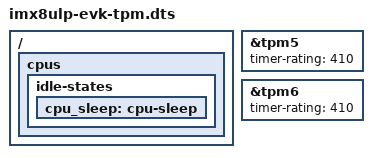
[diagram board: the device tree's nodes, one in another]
// SPDX-License-Identifier: (GPL-2.0+ OR MIT)
/*
 * Copyright 2024 NXP
 */

#include "imx8ulp-evk.dts"

/ {
	cpus {
		idle-states {
			cpu_sleep: cpu-sleep {
				/delete-property/ local-timer-stop;
			};
		};
	};
};

&tpm5 {
	timer-rating = <410>;
};

&tpm6 {
	timer-rating = <410>;
	status = "okay";
};
